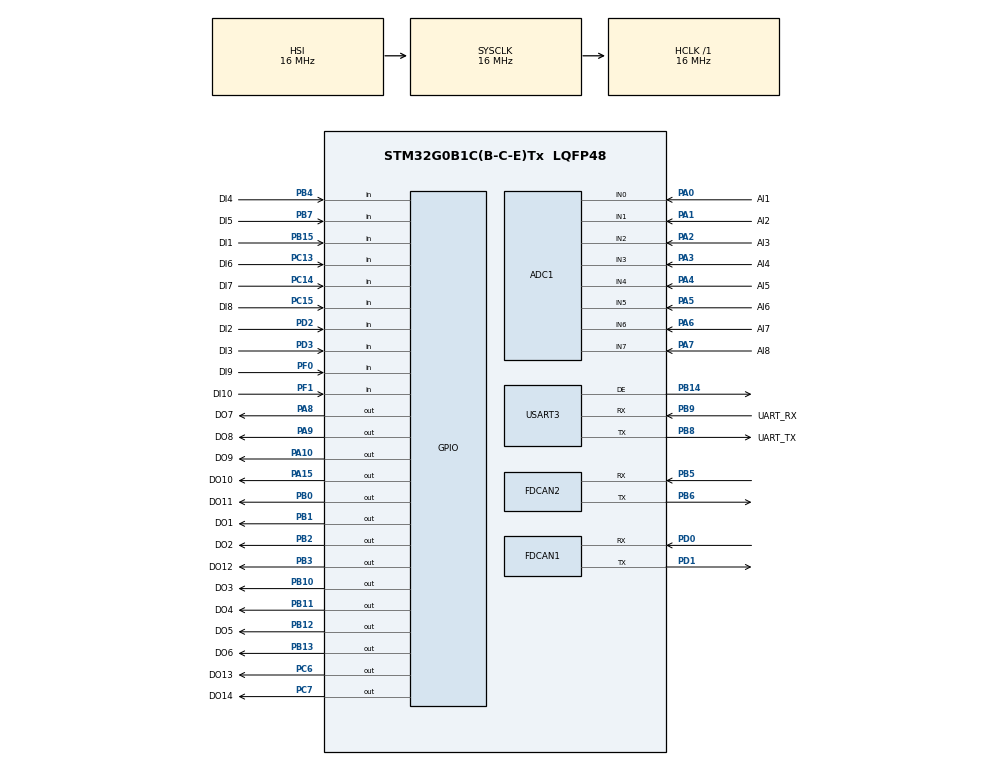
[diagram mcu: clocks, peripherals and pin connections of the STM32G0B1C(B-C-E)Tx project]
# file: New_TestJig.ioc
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ADC1.Channel-1\#ChannelRegularConversion=ADC_CHANNEL_0
ADC1.NbrOfConversionFlag=1
ADC1.Rank-1\#ChannelRegularConversion=1
ADC1.SamplingTime-1\#ChannelRegularConversion=ADC_SAMPLINGTIME_COMMON_1
ADC1.SelectedChannel=ADC_CHANNEL_0|ADC_CHANNEL_1|ADC_CHANNEL_2|ADC_CHANNEL_3|ADC_CHANNEL_4|ADC_CHANNEL_5|ADC_CHANNEL_6|ADC_CHANNEL_7
ADC1.master=1
FDCAN1.AutoRetransmission=ENABLE
FDCAN1.CalculateBaudRateNominal=250000
FDCAN1.CalculateTimeBitNominal=4000
FDCAN1.CalculateTimeQuantumNominal=250.0
FDCAN1.DataPrescaler=2
FDCAN1.DataTimeSeg1=1
FDCAN1.DataTimeSeg2=1
FDCAN1.Mode=FDCAN_MODE_NORMAL
FDCAN1.NominalPrescaler=4
FDCAN1.NominalSyncJumpWidth=2
FDCAN1.NominalTimeSeg1=13
FDCAN1.NominalTimeSeg2=2
FDCAN1.StdFiltersNbr=1
FDCAN2.AutoRetransmission=ENABLE
FDCAN2.CalculateBaudRateNominal=250000
FDCAN2.CalculateTimeBitNominal=4000
FDCAN2.CalculateTimeQuantumNominal=250.0
FDCAN2.NominalPrescaler=4
FDCAN2.NominalSyncJumpWidth=2
FDCAN2.NominalTimeSeg1=13
FDCAN2.NominalTimeSeg2=2
FDCAN2.StdFiltersNbr=1
Mcu.Family=STM32G0
Mcu.Name=STM32G0B1C(B-C-E)Tx
Mcu.Package=LQFP48
NVIC.TIM16_FDCAN_IT0_IRQn=true\:0\:0\:false\:false\:true\:true\:true\:true
NVIC.TIM17_FDCAN_IT1_IRQn=true\:0\:0\:false\:false\:true\:true\:true\:true
NVIC.USART3_4_5_6_LPUART1_IRQn=true\:0\:0\:false\:false\:true\:true\:true\:true
PA0.GPIO_Label=AI1
PA0.Mode=IN0
PA0.Signal=ADC1_IN0
PA1.GPIO_Label=AI2
PA1.Mode=IN1
PA1.Signal=ADC1_IN1
PA10.GPIO_Label=DO9
PA10.Signal=GPIO_Output
PA13.Mode=Serial_Wire
PA13.Signal=SYS_SWDIO
PA14-BOOT0.Mode=Serial_Wire
PA14-BOOT0.Signal=SYS_SWCLK
PA15.GPIO_Label=DO10
PA15.Signal=GPIO_Output
PA2.GPIO_Label=AI3
PA2.Mode=IN2
PA2.Signal=ADC1_IN2
PA3.GPIO_Label=AI4
PA3.Mode=IN3
PA3.Signal=ADC1_IN3
PA4.GPIO_Label=AI5
PA4.Mode=IN4
PA4.Signal=ADC1_IN4
PA5.GPIO_Label=AI6
PA5.Mode=IN5
PA5.Signal=ADC1_IN5
PA6.GPIO_Label=AI7
PA6.Mode=IN6
PA6.Signal=ADC1_IN6
PA7.GPIO_Label=AI8
PA7.Mode=IN7
PA7.Signal=ADC1_IN7
PA8.GPIO_Label=DO7
PA8.Signal=GPIO_Output
PA9.GPIO_Label=DO8
PA9.Signal=GPIO_Output
PB0.GPIO_Label=DO11
PB0.Signal=GPIO_Output
PB1.GPIO_Label=DO1
PB1.Signal=GPIO_Output
PB10.GPIO_Label=DO3
PB10.Signal=GPIO_Output
PB11.GPIO_Label=DO4
PB11.Signal=GPIO_Output
PB12.GPIO_Label=DO5
PB12.Signal=GPIO_Output
PB13.GPIO_Label=DO6
PB13.Signal=GPIO_Output
PB14.Mode=Hardware Flow Control (RS485)
PB14.Signal=USART3_DE
PB15.GPIO_Label=DI1
PB15.Signal=GPIO_Input
PB2.GPIO_Label=DO2
PB2.Signal=GPIO_Output
PB3.GPIO_Label=DO12
PB3.Signal=GPIO_Output
PB4.GPIO_Label=DI4
PB4.Signal=GPIO_Input
PB5.Mode=FDCAN_Activate
PB5.Signal=FDCAN2_RX
PB6.GPIO_FM6=__NULL
PB6.GPIO_Speed=GPIO_SPEED_FREQ_LOW
PB6.Mode=FDCAN_Activate
PB6.Signal=FDCAN2_TX
PB7.GPIO_Label=DI5
PB7.Signal=GPIO_Input
PB8.GPIO_Label=UART_TX
PB8.Mode=Asynchronous
PB8.Signal=USART3_TX
PB9.GPIO_Label=UART_RX
PB9.Mode=Asynchronous
PB9.Signal=USART3_RX
PC13.GPIO_Label=DI6
PC13.Signal=GPIO_Input
PC14-OSC32_IN\ (PC14).GPIO_Label=DI7
PC14-OSC32_IN\ (PC14).Signal=GPIO_Input
PC15-OSC32_OUT\ (PC15).GPIO_Label=DI8
PC15-OSC32_OUT\ (PC15).Signal=GPIO_Input
PC6.GPIO_Label=DO13
PC6.Signal=GPIO_Output
PC7.GPIO_Label=DO14
PC7.Signal=GPIO_Output
PD0.Mode=FDCAN_Activate
PD0.Signal=FDCAN1_RX
PD1.Mode=FDCAN_Activate
PD1.Signal=FDCAN1_TX
PD2.GPIO_Label=DI2
PD2.Signal=GPIO_Input
PD3.GPIO_Label=DI3
PD3.Signal=GPIO_Input
PF0-OSC_IN\ (PF0).GPIO_Label=DI9
PF0-OSC_IN\ (PF0).Signal=GPIO_Input
PF1-OSC_OUT\ (PF1).GPIO_Label=DI10
PF1-OSC_OUT\ (PF1).Signal=GPIO_Input
ProjectManager.HeapSize=0x200
ProjectManager.StackSize=0x400
ProjectManager.TargetToolchain=STM32CubeIDE
RCC.AHBFreq_Value=16000000
RCC.CortexFreq_Value=16000000
RCC.EXTERNAL_CLOCK_VALUE=48000
RCC.HCLKFreq_Value=16000000
RCC.HSE_VALUE=8000000
RCC.HSI48_VALUE=48000000
RCC.HSI_VALUE=16000000
RCC.LSE_VALUE=32768
RCC.SYSCLKFreq_VALUE=16000000
RCC.USBFreq_Value=48000000
RCC.VCOOutputFreq_Value=128000000
USART3.VirtualMode-Asynchronous=VM_ASYNC
USART3.VirtualMode-Hardware\ Flow\ Control\ (RS485)=VM_ASYNC
VP_SYS_VS_DBSignals.Mode=DisableDeadBatterySignals
board=custom

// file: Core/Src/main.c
/* USER CODE BEGIN Header */
/**
  ******************************************************************************
  * @file           : main.c
  * @brief          : Main program body
  ******************************************************************************
  * @attention
  *
  * Copyright (c) 2026 STMicroelectronics.
  * All rights reserved.
  *
  * This software is licensed under terms that can be found in the LICENSE file
  * in the root directory of this software component.
  * If no LICENSE file comes with this software, it is provided AS-IS.
  *
  ******************************************************************************
  */
/* USER CODE END Header */
#include "main.h"
#include "test_can.h"
#include "test_uart.h"

ADC_HandleTypeDef hadc1;

FDCAN_HandleTypeDef hfdcan1;
FDCAN_HandleTypeDef hfdcan2;

UART_HandleTypeDef huart3;

void SystemClock_Config(void);
static void MX_GPIO_Init(void);
static void MX_USART3_UART_Init(void);
static void MX_FDCAN1_Init(void);
static void MX_FDCAN2_Init(void);
static void MX_ADC1_Init(void);

/* USER CODE BEGIN 0 */
//#define BOARD_2 //  define on the target board
//#define RS485_TARGET // define on the target board
/* USER CODE END 0 */

int main(void)
{

  /* MCU Configuration--------------------------------------------------------*/

  /* Reset of all peripherals, Initializes the Flash interface and the Systick. */
  HAL_Init();

  /* Configure the system clock */
  SystemClock_Config();

  /* Initialize all configured peripherals */
  MX_GPIO_Init();
  MX_USART3_UART_Init();
  MX_FDCAN1_Init();
  MX_FDCAN2_Init();
  MX_ADC1_Init();
  /* USER CODE BEGIN 2 */
  CAN_Test_Init(&hfdcan1);
//  CAN_Test_Init(&hfdcan2);

  /* USER CODE END 2 */
//  uint8_t rx;
  /* Infinite loop */
  /* USER CODE BEGIN WHILE */
  while (1)
  {
//	  master board can test
	  CAN_Test_Board1_Run();
	      HAL_Delay(2000);

//	  target board can test
//	      CAN_Test_Board2_Run();

//	  master uart code
//	  UART_Test_Run(&huart1);
//	  HAL_Delay(1000);

// target side uart
//	  UART_Test_Run(&huart3);

//master side uart
	  UART_Test_Run(&huart3);
	  HAL_Delay(1000);
    /* USER CODE END WHILE */

  }
}

void SystemClock_Config(void)
{
  RCC_OscInitTypeDef RCC_OscInitStruct = {0};
  RCC_ClkInitTypeDef RCC_ClkInitStruct = {0};

  /** Configure the main internal regulator output voltage
  */
  HAL_PWREx_ControlVoltageScaling(PWR_REGULATOR_VOLTAGE_SCALE1);

  /** Initializes the RCC Oscillators according to the specified parameters
  * in the RCC_OscInitTypeDef structure.
  */
  RCC_OscInitStruct.OscillatorType = RCC_OSCILLATORTYPE_HSI;
  RCC_OscInitStruct.HSIState = RCC_HSI_ON;
  RCC_OscInitStruct.HSIDiv = RCC_HSI_DIV1;
  RCC_OscInitStruct.HSICalibrationValue = RCC_HSICALIBRATION_DEFAULT;
  RCC_OscInitStruct.PLL.PLLState = RCC_PLL_NONE;
  if (HAL_RCC_OscConfig(&RCC_OscInitStruct) != HAL_OK)
  {
    Error_Handler();
  }

  /** Initializes the CPU, AHB and APB buses clocks
  */
  RCC_ClkInitStruct.ClockType = RCC_CLOCKTYPE_HCLK|RCC_CLOCKTYPE_SYSCLK
                              |RCC_CLOCKTYPE_PCLK1;
  RCC_ClkInitStruct.SYSCLKSource = RCC_SYSCLKSOURCE_HSI;
  RCC_ClkInitStruct.AHBCLKDivider = RCC_SYSCLK_DIV1;
  RCC_ClkInitStruct.APB1CLKDivider = RCC_HCLK_DIV1;

  if (HAL_RCC_ClockConfig(&RCC_ClkInitStruct, FLASH_LATENCY_0) != HAL_OK)
  {
    Error_Handler();
  }
}

static void MX_ADC1_Init(void)
{

  ADC_ChannelConfTypeDef sConfig = {0};

  /** Configure the global features of the ADC (Clock, Resolution, Data Alignment and number of conversion)
  */
  hadc1.Instance = ADC1;
  hadc1.Init.ClockPrescaler = ADC_CLOCK_SYNC_PCLK_DIV2;
  hadc1.Init.Resolution = ADC_RESOLUTION_12B;
  hadc1.Init.DataAlign = ADC_DATAALIGN_RIGHT;
  hadc1.Init.ScanConvMode = ADC_SCAN_DISABLE;
  hadc1.Init.EOCSelection = ADC_EOC_SINGLE_CONV;
  hadc1.Init.LowPowerAutoWait = DISABLE;
  hadc1.Init.LowPowerAutoPowerOff = DISABLE;
  hadc1.Init.ContinuousConvMode = DISABLE;
  hadc1.Init.NbrOfConversion = 1;
  hadc1.Init.DiscontinuousConvMode = DISABLE;
  hadc1.Init.ExternalTrigConv = ADC_SOFTWARE_START;
  hadc1.Init.ExternalTrigConvEdge = ADC_EXTERNALTRIGCONVEDGE_NONE;
  hadc1.Init.DMAContinuousRequests = DISABLE;
  hadc1.Init.Overrun = ADC_OVR_DATA_PRESERVED;
  hadc1.Init.SamplingTimeCommon1 = ADC_SAMPLETIME_1CYCLE_5;
  hadc1.Init.SamplingTimeCommon2 = ADC_SAMPLETIME_1CYCLE_5;
  hadc1.Init.OversamplingMode = DISABLE;
  hadc1.Init.TriggerFrequencyMode = ADC_TRIGGER_FREQ_HIGH;
  if (HAL_ADC_Init(&hadc1) != HAL_OK)
  {
    Error_Handler();
  }

  /** Configure Regular Channel
  */
  sConfig.Channel = ADC_CHANNEL_0;
  sConfig.Rank = ADC_REGULAR_RANK_1;
  sConfig.SamplingTime = ADC_SAMPLINGTIME_COMMON_1;
  if (HAL_ADC_ConfigChannel(&hadc1, &sConfig) != HAL_OK)
  {
    Error_Handler();
  }

}

static void MX_FDCAN1_Init(void)
{

  hfdcan1.Instance = FDCAN1;
  hfdcan1.Init.ClockDivider = FDCAN_CLOCK_DIV1;
  hfdcan1.Init.FrameFormat = FDCAN_FRAME_CLASSIC;
  hfdcan1.Init.Mode = FDCAN_MODE_NORMAL;
  hfdcan1.Init.AutoRetransmission = ENABLE;
  hfdcan1.Init.TransmitPause = DISABLE;
  hfdcan1.Init.ProtocolException = DISABLE;
  hfdcan1.Init.NominalPrescaler = 4;
  hfdcan1.Init.NominalSyncJumpWidth = 2;
  hfdcan1.Init.NominalTimeSeg1 = 13;
  hfdcan1.Init.NominalTimeSeg2 = 2;
  hfdcan1.Init.DataPrescaler = 2;
  hfdcan1.Init.DataSyncJumpWidth = 1;
  hfdcan1.Init.DataTimeSeg1 = 1;
  hfdcan1.Init.DataTimeSeg2 = 1;
  hfdcan1.Init.StdFiltersNbr = 1;
  hfdcan1.Init.ExtFiltersNbr = 0;
  hfdcan1.Init.TxFifoQueueMode = FDCAN_TX_FIFO_OPERATION;
  if (HAL_FDCAN_Init(&hfdcan1) != HAL_OK)
  {
    Error_Handler();
  }

}

static void MX_FDCAN2_Init(void)
{

  hfdcan2.Instance = FDCAN2;
  hfdcan2.Init.ClockDivider = FDCAN_CLOCK_DIV1;
  hfdcan2.Init.FrameFormat = FDCAN_FRAME_CLASSIC;
  hfdcan2.Init.Mode = FDCAN_MODE_NORMAL;
  hfdcan2.Init.AutoRetransmission = ENABLE;
  hfdcan2.Init.TransmitPause = DISABLE;
  hfdcan2.Init.ProtocolException = DISABLE;
  hfdcan2.Init.NominalPrescaler = 4;
  hfdcan2.Init.NominalSyncJumpWidth = 2;
  hfdcan2.Init.NominalTimeSeg1 = 13;
  hfdcan2.Init.NominalTimeSeg2 = 2;
  hfdcan2.Init.DataPrescaler = 1;
  hfdcan2.Init.DataSyncJumpWidth = 1;
  hfdcan2.Init.DataTimeSeg1 = 1;
  hfdcan2.Init.DataTimeSeg2 = 1;
  hfdcan2.Init.StdFiltersNbr = 1;
  hfdcan2.Init.ExtFiltersNbr = 0;
  hfdcan2.Init.TxFifoQueueMode = FDCAN_TX_FIFO_OPERATION;
  if (HAL_FDCAN_Init(&hfdcan2) != HAL_OK)
  {
    Error_Handler();
  }

}

static void MX_USART3_UART_Init(void)
{

  huart3.Instance = USART3;
  huart3.Init.BaudRate = 115200;
  huart3.Init.WordLength = UART_WORDLENGTH_8B;
  huart3.Init.StopBits = UART_STOPBITS_1;
  huart3.Init.Parity = UART_PARITY_NONE;
  huart3.Init.Mode = UART_MODE_TX_RX;
  huart3.Init.HwFlowCtl = UART_HWCONTROL_NONE;
  huart3.Init.OverSampling = UART_OVERSAMPLING_16;
  huart3.Init.OneBitSampling = UART_ONE_BIT_SAMPLE_DISABLE;
  huart3.Init.ClockPrescaler = UART_PRESCALER_DIV1;
  huart3.AdvancedInit.AdvFeatureInit = UART_ADVFEATURE_NO_INIT;
  if (HAL_RS485Ex_Init(&huart3, UART_DE_POLARITY_HIGH, 0, 0) != HAL_OK)
  {
    Error_Handler();
  }
  if (HAL_UARTEx_SetTxFifoThreshold(&huart3, UART_TXFIFO_THRESHOLD_1_8) != HAL_OK)
  {
    Error_Handler();
  }
  if (HAL_UARTEx_SetRxFifoThreshold(&huart3, UART_RXFIFO_THRESHOLD_1_8) != HAL_OK)
  {
    Error_Handler();
  }
  if (HAL_UARTEx_DisableFifoMode(&huart3) != HAL_OK)
  {
    Error_Handler();
  }

}

static void MX_GPIO_Init(void)
{
  GPIO_InitTypeDef GPIO_InitStruct = {0};

  /* GPIO Ports Clock Enable */
  __HAL_RCC_GPIOC_CLK_ENABLE();
  __HAL_RCC_GPIOF_CLK_ENABLE();
  __HAL_RCC_GPIOA_CLK_ENABLE();
  __HAL_RCC_GPIOB_CLK_ENABLE();
  __HAL_RCC_GPIOD_CLK_ENABLE();

  /*Configure GPIO pin Output Level */
  HAL_GPIO_WritePin(GPIOB, DO11_Pin|DO1_Pin|DO2_Pin|DO3_Pin
                          |DO4_Pin|DO5_Pin|DO6_Pin|DO12_Pin, GPIO_PIN_RESET);

  /*Configure GPIO pin Output Level */
  HAL_GPIO_WritePin(GPIOA, DO7_Pin|DO8_Pin|DO9_Pin|DO10_Pin, GPIO_PIN_RESET);

  /*Configure GPIO pin Output Level */
  HAL_GPIO_WritePin(GPIOC, DO13_Pin|DO14_Pin, GPIO_PIN_RESET);

  /*Configure GPIO pins : DI6_Pin DI7_Pin DI8_Pin */
  GPIO_InitStruct.Pin = DI6_Pin|DI7_Pin|DI8_Pin;
  GPIO_InitStruct.Mode = GPIO_MODE_INPUT;
  GPIO_InitStruct.Pull = GPIO_NOPULL;
  HAL_GPIO_Init(GPIOC, &GPIO_InitStruct);

  /*Configure GPIO pins : DI9_Pin DI10_Pin */
  GPIO_InitStruct.Pin = DI9_Pin|DI10_Pin;
  GPIO_InitStruct.Mode = GPIO_MODE_INPUT;
  GPIO_InitStruct.Pull = GPIO_NOPULL;
  HAL_GPIO_Init(GPIOF, &GPIO_InitStruct);

  /*Configure GPIO pins : DO11_Pin DO1_Pin DO2_Pin DO3_Pin
                           DO4_Pin DO5_Pin DO6_Pin DO12_Pin */
  GPIO_InitStruct.Pin = DO11_Pin|DO1_Pin|DO2_Pin|DO3_Pin
                          |DO4_Pin|DO5_Pin|DO6_Pin|DO12_Pin;
  GPIO_InitStruct.Mode = GPIO_MODE_OUTPUT_PP;
  GPIO_InitStruct.Pull = GPIO_NOPULL;
  GPIO_InitStruct.Speed = GPIO_SPEED_FREQ_LOW;
  HAL_GPIO_Init(GPIOB, &GPIO_InitStruct);

  /*Configure GPIO pins : DI1_Pin DI4_Pin DI5_Pin */
  GPIO_InitStruct.Pin = DI1_Pin|DI4_Pin|DI5_Pin;
  GPIO_InitStruct.Mode = GPIO_MODE_INPUT;
  GPIO_InitStruct.Pull = GPIO_NOPULL;
  HAL_GPIO_Init(GPIOB, &GPIO_InitStruct);

  /*Configure GPIO pins : DO7_Pin DO8_Pin DO9_Pin DO10_Pin */
  GPIO_InitStruct.Pin = DO7_Pin|DO8_Pin|DO9_Pin|DO10_Pin;
  GPIO_InitStruct.Mode = GPIO_MODE_OUTPUT_PP;
  GPIO_InitStruct.Pull = GPIO_NOPULL;
  GPIO_InitStruct.Speed = GPIO_SPEED_FREQ_LOW;
  HAL_GPIO_Init(GPIOA, &GPIO_InitStruct);

  /*Configure GPIO pins : DO13_Pin DO14_Pin */
  GPIO_InitStruct.Pin = DO13_Pin|DO14_Pin;
  GPIO_InitStruct.Mode = GPIO_MODE_OUTPUT_PP;
  GPIO_InitStruct.Pull = GPIO_NOPULL;
  GPIO_InitStruct.Speed = GPIO_SPEED_FREQ_LOW;
  HAL_GPIO_Init(GPIOC, &GPIO_InitStruct);

  /*Configure GPIO pins : DI2_Pin DI3_Pin */
  GPIO_InitStruct.Pin = DI2_Pin|DI3_Pin;
  GPIO_InitStruct.Mode = GPIO_MODE_INPUT;
  GPIO_InitStruct.Pull = GPIO_NOPULL;
  HAL_GPIO_Init(GPIOD, &GPIO_InitStruct);

}

void Error_Handler(void)
{
  __disable_irq();
  while (1)
  {
  }
}
